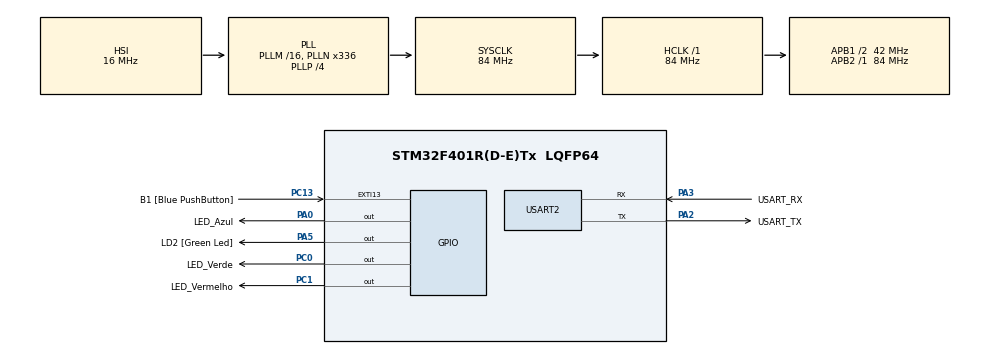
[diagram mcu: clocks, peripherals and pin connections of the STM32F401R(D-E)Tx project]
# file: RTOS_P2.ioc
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FREERTOS.Tasks01=RTOS_LedAzul,8,128,StartRTOS_LedAzul,Default,NULL,Dynamic,NULL,NULL;RTOS_LedVermelh,16,128,StartRTOS_LedVermelho,Default,NULL,Dynamic,NULL,NULL;RTOS_LedVerde,24,128,StartRTOS_LedVerde,Default,NULL,Dynamic,NULL,NULL;Task04,32,128,StartTask4,Default,NULL,Dynamic,NULL,NULL
FREERTOS.configUSE_NEWLIB_REENTRANT=1
Mcu.Family=STM32F4
Mcu.Name=STM32F401R(D-E)Tx
Mcu.Package=LQFP64
NVIC.PriorityGroup=NVIC_PRIORITYGROUP_4
NVIC.TIM1_BRK_TIM9_IRQn=true\:15\:0\:false\:false\:true\:false\:false\:true\:true
NVIC.TimeBase=TIM1_BRK_TIM9_IRQn
NVIC.TimeBaseIP=TIM9
PA0-WKUP.GPIO_Label=LED_Azul
PA0-WKUP.Signal=GPIO_Output
PA13.GPIO_Label=TMS
PA13.Mode=Trace_Asynchronous_SW
PA13.Signal=SYS_JTMS-SWDIO
PA14.GPIO_Label=TCK
PA14.Mode=Trace_Asynchronous_SW
PA14.Signal=SYS_JTCK-SWCLK
PA2.GPIO_Label=USART_TX
PA2.GPIO_Mode=GPIO_MODE_AF_PP
PA2.GPIO_PuPd=GPIO_NOPULL
PA2.GPIO_Speed=GPIO_SPEED_FREQ_LOW
PA2.Mode=Asynchronous
PA2.Signal=USART2_TX
PA3.GPIO_Label=USART_RX
PA3.GPIO_Mode=GPIO_MODE_AF_PP
PA3.GPIO_PuPd=GPIO_NOPULL
PA3.GPIO_Speed=GPIO_SPEED_FREQ_LOW
PA3.Mode=Asynchronous
PA3.Signal=USART2_RX
PA5.GPIO_Label=LD2 [Green Led]
PA5.GPIO_Mode=GPIO_MODE_OUTPUT_PP
PA5.GPIO_PuPd=GPIO_NOPULL
PA5.GPIO_Speed=GPIO_SPEED_FREQ_LOW
PA5.Signal=GPIO_Output
PB3.GPIO_Label=SWO
PB3.Mode=Trace_Asynchronous_SW
PB3.Signal=SYS_JTDO-SWO
PC0.GPIO_Label=LED_Verde
PC0.Signal=GPIO_Output
PC1.GPIO_Label=LED_Vermelho
PC1.Signal=GPIO_Output
PC13-ANTI_TAMP.GPIO_Label=B1 [Blue PushButton]
PC13-ANTI_TAMP.GPIO_ModeDefaultEXTI=GPIO_MODE_IT_FALLING
PC13-ANTI_TAMP.GPIO_PuPd=GPIO_NOPULL
PC13-ANTI_TAMP.Signal=GPXTI13
PC14-OSC32_IN.Mode=LSE-External-Oscillator
PC14-OSC32_IN.Signal=RCC_OSC32_IN
PC15-OSC32_OUT.Mode=LSE-External-Oscillator
PC15-OSC32_OUT.Signal=RCC_OSC32_OUT
PH0\ -\ OSC_IN.Mode=HSE-External-Clock-Source
PH0\ -\ OSC_IN.Signal=RCC_OSC_IN
PH1\ -\ OSC_OUT.Mode=HSE-External-Clock-Source
PH1\ -\ OSC_OUT.Signal=RCC_OSC_OUT
ProjectManager.HeapSize=0x200
ProjectManager.StackSize=0x400
ProjectManager.TargetToolchain=STM32CubeIDE
RCC.48MHZClocksFreq_Value=48000000
RCC.AHBFreq_Value=84000000
RCC.APB1CLKDivider=RCC_HCLK_DIV2
RCC.APB1Freq_Value=42000000
RCC.APB1TimFreq_Value=84000000
RCC.APB2Freq_Value=84000000
RCC.APB2TimFreq_Value=84000000
RCC.CortexFreq_Value=84000000
RCC.HCLKFreq_Value=84000000
RCC.HSE_VALUE=8000000
RCC.HSI_VALUE=16000000
RCC.PLLN=336
RCC.PLLP=RCC_PLLP_DIV4
RCC.PLLQ=7
RCC.SYSCLKFreq_VALUE=84000000
RCC.SYSCLKSource=RCC_SYSCLKSOURCE_PLLCLK
RCC.VCOOutputFreq_Value=336000000
USART2.VirtualMode=VM_ASYNC
VP_FREERTOS_VS_CMSIS_V2.Mode=CMSIS_V2
VP_SYS_VS_tim9.Mode=TIM9
board=NUCLEO-F401RE

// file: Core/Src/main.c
/* USER CODE BEGIN Header */
/**
  ******************************************************************************
  * @file           : main.c
  * @brief          : Main program body
  ******************************************************************************
  * @attention
  *
  * Copyright (c) 2026 STMicroelectronics.
  * All rights reserved.
  *
  * This software is licensed under terms that can be found in the LICENSE file
  * in the root directory of this software component.
  * If no LICENSE file comes with this software, it is provided AS-IS.
  *
  ******************************************************************************
  */
/* USER CODE END Header */
#include "main.h"
#include "cmsis_os.h"

UART_HandleTypeDef huart2;

/* Definitions for RTOS_LedAzul */
osThreadId_t RTOS_LedAzulHandle;
const osThreadAttr_t RTOS_LedAzul_attributes = {
  .name = "RTOS_LedAzul",
  .stack_size = 128 * 4,
  .priority = (osPriority_t) osPriorityLow,
};
/* Definitions for RTOS_LedVermelh */
osThreadId_t RTOS_LedVermelhHandle;
const osThreadAttr_t RTOS_LedVermelh_attributes = {
  .name = "RTOS_LedVermelh",
  .stack_size = 128 * 4,
  .priority = (osPriority_t) osPriorityBelowNormal,
};
/* Definitions for RTOS_LedVerde */
osThreadId_t RTOS_LedVerdeHandle;
const osThreadAttr_t RTOS_LedVerde_attributes = {
  .name = "RTOS_LedVerde",
  .stack_size = 128 * 4,
  .priority = (osPriority_t) osPriorityNormal,
};
/* Definitions for Task04 */
osThreadId_t Task04Handle;
const osThreadAttr_t Task04_attributes = {
  .name = "Task04",
  .stack_size = 128 * 4,
  .priority = (osPriority_t) osPriorityAboveNormal,
};

void SystemClock_Config(void);
static void MX_GPIO_Init(void);
static void MX_USART2_UART_Init(void);
void StartRTOS_LedAzul(void *argument);
void StartRTOS_LedVermelho(void *argument);
void StartRTOS_LedVerde(void *argument);
void StartTask4(void *argument);

int main(void)
{

  /* MCU Configuration--------------------------------------------------------*/

  /* Reset of all peripherals, Initializes the Flash interface and the Systick. */
  HAL_Init();

  /* Configure the system clock */
  SystemClock_Config();

  /* Initialize all configured peripherals */
  MX_GPIO_Init();
  MX_USART2_UART_Init();

  /* Init scheduler */
  osKernelInitialize();

  /* Create the thread(s) */
  /* creation of RTOS_LedAzul */
  RTOS_LedAzulHandle = osThreadNew(StartRTOS_LedAzul, NULL, &RTOS_LedAzul_attributes);

  /* creation of RTOS_LedVermelh */
  RTOS_LedVermelhHandle = osThreadNew(StartRTOS_LedVermelho, NULL, &RTOS_LedVermelh_attributes);

  /* creation of RTOS_LedVerde */
  RTOS_LedVerdeHandle = osThreadNew(StartRTOS_LedVerde, NULL, &RTOS_LedVerde_attributes);

  /* creation of Task04 */
  Task04Handle = osThreadNew(StartTask4, NULL, &Task04_attributes);

  /* Start scheduler */
  osKernelStart();

  /* We should never get here as control is now taken by the scheduler */

  /* Infinite loop */
  while (1)
  {

    /* USER CODE BEGIN 3 */

	  // No FreeRTOS o lupe pincipal while nunca ser executado
	  /*HAL_GPIO_TogglePin(GPIOC, LED_Vermelho_Pin);
	    HAL_Delay(500);
	   */
  }
  /* USER CODE END 3 */
}

void SystemClock_Config(void)
{
  RCC_OscInitTypeDef RCC_OscInitStruct = {0};
  RCC_ClkInitTypeDef RCC_ClkInitStruct = {0};

  /** Configure the main internal regulator output voltage
  */
  __HAL_RCC_PWR_CLK_ENABLE();
  __HAL_PWR_VOLTAGESCALING_CONFIG(PWR_REGULATOR_VOLTAGE_SCALE2);

  /** Initializes the RCC Oscillators according to the specified parameters
  * in the RCC_OscInitTypeDef structure.
  */
  RCC_OscInitStruct.OscillatorType = RCC_OSCILLATORTYPE_HSI;
  RCC_OscInitStruct.HSIState = RCC_HSI_ON;
  RCC_OscInitStruct.HSICalibrationValue = RCC_HSICALIBRATION_DEFAULT;
  RCC_OscInitStruct.PLL.PLLState = RCC_PLL_ON;
  RCC_OscInitStruct.PLL.PLLSource = RCC_PLLSOURCE_HSI;
  RCC_OscInitStruct.PLL.PLLM = 16;
  RCC_OscInitStruct.PLL.PLLN = 336;
  RCC_OscInitStruct.PLL.PLLP = RCC_PLLP_DIV4;
  RCC_OscInitStruct.PLL.PLLQ = 7;
  if (HAL_RCC_OscConfig(&RCC_OscInitStruct) != HAL_OK)
  {
    Error_Handler();
  }

  /** Initializes the CPU, AHB and APB buses clocks
  */
  RCC_ClkInitStruct.ClockType = RCC_CLOCKTYPE_HCLK|RCC_CLOCKTYPE_SYSCLK
                              |RCC_CLOCKTYPE_PCLK1|RCC_CLOCKTYPE_PCLK2;
  RCC_ClkInitStruct.SYSCLKSource = RCC_SYSCLKSOURCE_PLLCLK;
  RCC_ClkInitStruct.AHBCLKDivider = RCC_SYSCLK_DIV1;
  RCC_ClkInitStruct.APB1CLKDivider = RCC_HCLK_DIV2;
  RCC_ClkInitStruct.APB2CLKDivider = RCC_HCLK_DIV1;

  if (HAL_RCC_ClockConfig(&RCC_ClkInitStruct, FLASH_LATENCY_2) != HAL_OK)
  {
    Error_Handler();
  }
}

static void MX_USART2_UART_Init(void)
{

  huart2.Instance = USART2;
  huart2.Init.BaudRate = 115200;
  huart2.Init.WordLength = UART_WORDLENGTH_8B;
  huart2.Init.StopBits = UART_STOPBITS_1;
  huart2.Init.Parity = UART_PARITY_NONE;
  huart2.Init.Mode = UART_MODE_TX_RX;
  huart2.Init.HwFlowCtl = UART_HWCONTROL_NONE;
  huart2.Init.OverSampling = UART_OVERSAMPLING_16;
  if (HAL_UART_Init(&huart2) != HAL_OK)
  {
    Error_Handler();
  }

}

static void MX_GPIO_Init(void)
{
  GPIO_InitTypeDef GPIO_InitStruct = {0};

  /* GPIO Ports Clock Enable */
  __HAL_RCC_GPIOC_CLK_ENABLE();
  __HAL_RCC_GPIOH_CLK_ENABLE();
  __HAL_RCC_GPIOA_CLK_ENABLE();
  __HAL_RCC_GPIOB_CLK_ENABLE();

  /*Configure GPIO pin Output Level */
  HAL_GPIO_WritePin(GPIOC, LED_Verde_Pin|LED_Vermelho_Pin, GPIO_PIN_RESET);

  /*Configure GPIO pin Output Level */
  HAL_GPIO_WritePin(GPIOA, LED_Azul_Pin|LD2_Pin, GPIO_PIN_RESET);

  /*Configure GPIO pin : B1_Pin */
  GPIO_InitStruct.Pin = B1_Pin;
  GPIO_InitStruct.Mode = GPIO_MODE_IT_FALLING;
  GPIO_InitStruct.Pull = GPIO_NOPULL;
  HAL_GPIO_Init(B1_GPIO_Port, &GPIO_InitStruct);

  /*Configure GPIO pins : LED_Verde_Pin LED_Vermelho_Pin */
  GPIO_InitStruct.Pin = LED_Verde_Pin|LED_Vermelho_Pin;
  GPIO_InitStruct.Mode = GPIO_MODE_OUTPUT_PP;
  GPIO_InitStruct.Pull = GPIO_NOPULL;
  GPIO_InitStruct.Speed = GPIO_SPEED_FREQ_LOW;
  HAL_GPIO_Init(GPIOC, &GPIO_InitStruct);

  /*Configure GPIO pins : LED_Azul_Pin LD2_Pin */
  GPIO_InitStruct.Pin = LED_Azul_Pin|LD2_Pin;
  GPIO_InitStruct.Mode = GPIO_MODE_OUTPUT_PP;
  GPIO_InitStruct.Pull = GPIO_NOPULL;
  GPIO_InitStruct.Speed = GPIO_SPEED_FREQ_LOW;
  HAL_GPIO_Init(GPIOA, &GPIO_InitStruct);

}

void StartRTOS_LedAzul(void *argument)
{
  /* USER CODE BEGIN 5 */
  /* Infinite loop */
  for(;;)
  {

	//variavel volation dentro dessa trade
	//volatile uint32_t espere = 50000000;

	//Led azul Protoboard Porta A LED_Azul só per pino no cubeMX
	HAL_GPIO_TogglePin(GPIOA, LED_Azul_Pin);
	osDelay(1000);

	//decrementa o espera e a tarefa fica presa aqui
	//essa tarefa LED_Azul tem prioridade low
	//while(espere--);
  }
  /* USER CODE END 5 */
}

void StartRTOS_LedVermelho(void *argument)
{
  /* USER CODE BEGIN StartRTOS_LedVermelho */
  /* Infinite loop */
  for(;;)
  {
		HAL_GPIO_TogglePin(GPIOC, LED_Vermelho_Pin);
			osDelay(500);
  }
  /* USER CODE END StartRTOS_LedVermelho */
}

void StartRTOS_LedVerde(void *argument)
{
  /* USER CODE BEGIN StartRTOS_LedVerde */
  /* Infinite loop */
  for(;;)
  {

	  //testa a prioridade dessa tarefa que é maior que a tarefa 01 e 02
	  volatile uint32_t espere = 50000000;

	  HAL_GPIO_TogglePin(GPIOC, LED_Verde_Pin);
      osDelay(200);

      //loop de tempo de 50000000
      while(espere--);
  }
  /* USER CODE END StartRTOS_LedVerde */
}

void StartTask4(void *argument)
{
  /* USER CODE BEGIN StartTask4 */
  /* Infinite loop */
  for(;;)
  {

	  // nesse exemplo como a tarefa 04 ela tem prioridade mais alta que todas as outras 03
	  // vamos usar ela pra suspender a 03 sendo assim a 01 e 02 funciona
	  osDelay(1000);
	  //suspende tarefa 03
	  osThreadSuspend(RTOS_LedVerdeHandle);
	  osDelay(5000);
	  //volta tarefa 03
	  osThreadResume(RTOS_LedVerdeHandle);
  }
  /* USER CODE END StartTask4 */
}

void HAL_TIM_PeriodElapsedCallback(TIM_HandleTypeDef *htim)
{
  if (htim->Instance == TIM9)
  {
    HAL_IncTick();
  }
}

void Error_Handler(void)
{
  __disable_irq();
  while (1)
  {
  }
}
